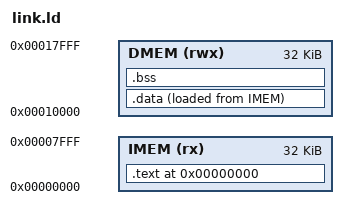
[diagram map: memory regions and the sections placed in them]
/* ==========================================================================
 * link.ld — RV32I 裸机链接脚本
 *
 * 内存映射（对应 bus_interconnect.v）:
 *   IMEM : 0x00000000 – 0x00007FFF  32KB  可执行/只读 (imem.v 块RAM)
 *   DMEM : 0x00010000 – 0x00017FFF  32KB  读写数据    (dmem.v 块RAM)
 *
 * .data 段 LMA 存在 IMEM（随镜像烧写），运行时由 crt0 复制到 DMEM VMA。
 * ========================================================================= */

OUTPUT_ARCH(riscv)
ENTRY(_start)

MEMORY {
    IMEM (rx)  : ORIGIN = 0x00000000, LENGTH = 32K
    DMEM (rwx) : ORIGIN = 0x00010000, LENGTH = 32K
}

SECTIONS {
    /* ------------------------------------------------------------------ */
    /* .text : 代码段 + 只读数据（放在 IMEM）                             */
    /* ------------------------------------------------------------------ */
    .text 0x00000000 : {
        KEEP(*(.text.start))        /* crt0._start 必须位于地址 0        */
        *(.text*)
        *(.rodata*)
        *(.srodata*)
        . = ALIGN(4);
    } > IMEM

    /* 记录 .text 段末尾（用于大小检查） */
    _text_end = .;

    /* ------------------------------------------------------------------ */
    /* .data : 初始化数据                                                  */
    /* VMA = DMEM（运行地址），LMA = IMEM（存储地址，紧跟 .text）         */
    /* ------------------------------------------------------------------ */
    .data : {
        _data_start = .;            /* VMA 起址（DMEM 侧）                */
        *(.data*)
        *(.sdata*)
        . = ALIGN(4);
        _data_end = .;              /* VMA 末址                            */
    } > DMEM AT > IMEM              /* AT > IMEM: LMA 存在 IMEM 空间      */

    /* .data 段的 LMA（IMEM 中的加载地址），供 crt0 使用 */
    _data_lma = LOADADDR(.data);

    /* ------------------------------------------------------------------ */
    /* .bss : 未初始化数据（不占 IMEM 镜像空间，由 crt0 清零）            */
    /* ------------------------------------------------------------------ */
    .bss (NOLOAD) : {
        _bss_start = .;
        *(.bss*)
        *(.sbss*)
        *(COMMON)
        . = ALIGN(4);
        _bss_end = .;
    } > DMEM

    /* ------------------------------------------------------------------ */
    /* 栈顶：DMEM 末端（向低地址生长）                                    */
    /* ------------------------------------------------------------------ */
    _stack_top = ORIGIN(DMEM) + LENGTH(DMEM);   /* = 0x00018000         */

    /* ------------------------------------------------------------------ */
    /* 丢弃不需要的段                                                      */
    /* ------------------------------------------------------------------ */
    /DISCARD/ : {
        *(.eh_frame)
        *(.eh_frame_hdr)
        *(.comment)
        *(.note*)
        *(.riscv.attributes)
    }

    /* ------------------------------------------------------------------ */
    /* 尺寸检查 ASSERT（防止溢出 IMEM 或 DMEM）                           */
    /* ------------------------------------------------------------------ */
    ASSERT(_text_end + (_data_end - _data_start) <= 0x8000,
           "ERROR: IMEM overflow! .text + .data > 32KB")
    ASSERT(_bss_end <= 0x18000,
           "ERROR: DMEM overflow! .data + .bss > 32KB")
    ASSERT(_stack_top - _bss_end >= 0x1000,
           "ERROR: Stack space < 4KB, consider reducing ITERATIONS or DMEM data")
}
